# ESP32-C2 register map
Vendor: ESPRESSIF SYSTEMS (SHANGHAI) CO., LTD.; Series: ESP32-C2; File version: 4
CPU: RV32IMC r0p0, little endian, no MPU, no FPU, 4 interrupt priority bits
Address unit: 32 bits
Registers are 32-bit, read-write, reset 0x0 unless marked. A register's access mark holds for its fields unless they carry their own. Offsets are from the block's base; [hi:lo] are bit positions; {n}, {i} and the like mark numbered series.

## APB_CTRL — Advanced Peripheral Bus Controller
Base 0x60026000
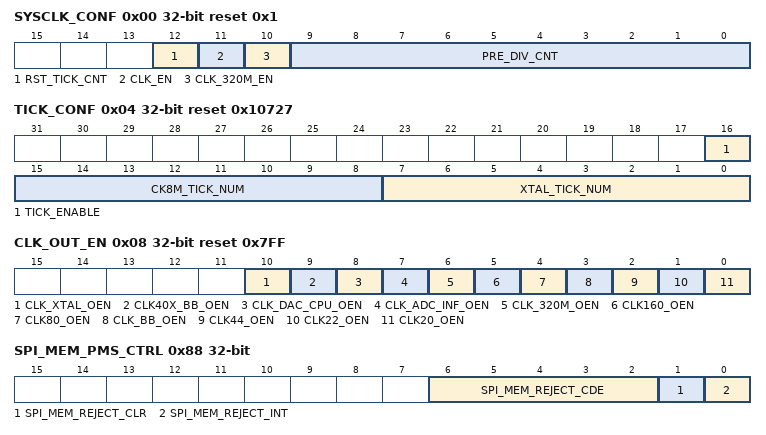
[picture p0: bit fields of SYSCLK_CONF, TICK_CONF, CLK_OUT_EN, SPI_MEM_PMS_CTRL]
0x00 SYSCLK_CONF reset 0x1 — APB_CTRL_SYSCLK_CONF_REG
  [12] RST_TICK_CNT — reg_rst_tick_cnt
  [11] CLK_EN — reg_clk_en
  [10] CLK_320M_EN — reg_clk_320m_en
  [9:0] PRE_DIV_CNT — reg_pre_div_cnt
0x04 TICK_CONF reset 0x10727 — APB_CTRL_TICK_CONF_REG
  [16] TICK_ENABLE — reg_tick_enable
  [15:8] CK8M_TICK_NUM — reg_ck8m_tick_num
  [7:0] XTAL_TICK_NUM — reg_xtal_tick_num
0x08 CLK_OUT_EN reset 0x7FF — APB_CTRL_CLK_OUT_EN_REG
  [10] CLK_XTAL_OEN — reg_clk_xtal_oen
  [9] CLK40X_BB_OEN — reg_clk40x_bb_oen
  [8] CLK_DAC_CPU_OEN — reg_clk_dac_cpu_oen
  [7] CLK_ADC_INF_OEN — reg_clk_adc_inf_oen
  [6] CLK_320M_OEN — reg_clk_320m_oen
  [5] CLK160_OEN — reg_clk160_oen
  [4] CLK80_OEN — reg_clk80_oen
  [3] CLK_BB_OEN — reg_clk_bb_oen
  [2] CLK44_OEN — reg_clk44_oen
  [1] CLK22_OEN — reg_clk22_oen
  [0] CLK20_OEN — reg_clk20_oen
0x0C WIFI_BB_CFG — APB_CTRL_WIFI_BB_CFG_REG
  [31:0] WIFI_BB_CFG — reg_wifi_bb_cfg
0x10 WIFI_BB_CFG_2 — APB_CTRL_WIFI_BB_CFG_2_REG
  [31:0] WIFI_BB_CFG_2 — reg_wifi_bb_cfg_2
0x14 WIFI_CLK_EN reset 0xFFFCE030 — APB_CTRL_WIFI_CLK_EN_REG
  [31:0] WIFI_CLK_EN — reg_wifi_clk_en
0x18 WIFI_RST_EN — APB_CTRL_WIFI_RST_EN_REG
  [31:0] WIFI_RST — reg_wifi_rst
0x1C HOST_INF_SEL — APB_CTRL_HOST_INF_SEL_REG
  [7:0] PERI_IO_SWAP — reg_peri_io_swap
0x20 EXT_MEM_PMS_LOCK — APB_CTRL_EXT_MEM_PMS_LOCK_REG
  [0] EXT_MEM_PMS_LOCK — reg_ext_mem_pms_lock
{0x28+4i} FLASH_ACE{i}_ATTR reset 0x3 (i=0..3) — APB_CTRL_FLASH_ACE{i}_ATTR_REG
  [1:0] FLASH_ACE{i}_ATTR — reg_flash_ace{i}_attr
0x38 FLASH_ACE0_ADDR — APB_CTRL_FLASH_ACE0_ADDR_REG
  [31:0] S — reg_flash_ace0_addr_s
0x3C FLASH_ACE1_ADDR reset 0x400000 — APB_CTRL_FLASH_ACE1_ADDR_REG
  [31:0] S — reg_flash_ace1_addr_s
0x40 FLASH_ACE2_ADDR reset 0x800000 — APB_CTRL_FLASH_ACE2_ADDR_REG
  [31:0] S — reg_flash_ace2_addr_s
0x44 FLASH_ACE3_ADDR reset 0xC00000 — APB_CTRL_FLASH_ACE3_ADDR_REG
  [31:0] S — reg_flash_ace3_addr_s
{0x48+4i} FLASH_ACE{i}_SIZE reset 0x400 (i=0..3) — APB_CTRL_FLASH_ACE{i}_SIZE_REG
  [12:0] FLASH_ACE{i}_SIZE — reg_flash_ace{i}_size
0x88 SPI_MEM_PMS_CTRL access per field — APB_CTRL_SPI_MEM_PMS_CTRL_REG
  [6:2] SPI_MEM_REJECT_CDE ro — reg_spi_mem_reject_cde
  [1] SPI_MEM_REJECT_CLR wo — reg_spi_mem_reject_clr
  [0] SPI_MEM_REJECT_INT ro — reg_spi_mem_reject_int
0x8C SPI_MEM_REJECT_ADDR ro — APB_CTRL_SPI_MEM_REJECT_ADDR_REG
  [31:0] SPI_MEM_REJECT_ADDR — reg_spi_mem_reject_addr
0x90 SDIO_CTRL — APB_CTRL_SDIO_CTRL_REG
  [0] SDIO_WIN_ACCESS_EN — reg_sdio_win_access_en
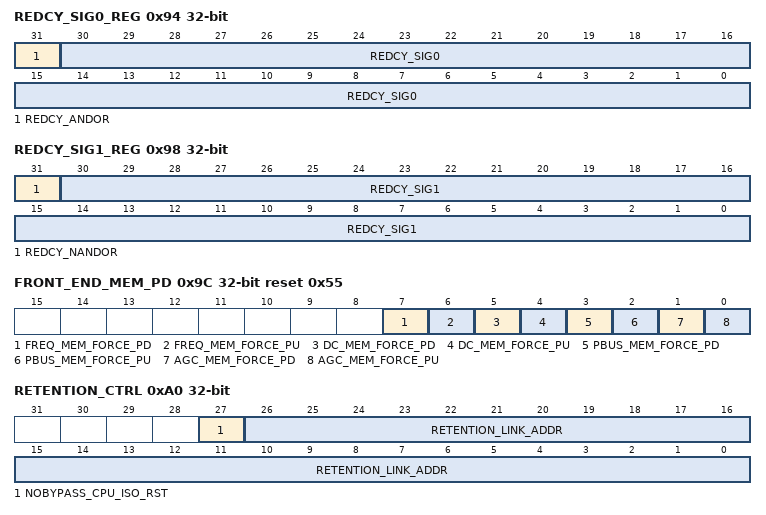
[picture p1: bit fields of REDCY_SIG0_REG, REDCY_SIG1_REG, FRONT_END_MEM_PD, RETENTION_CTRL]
0x94 REDCY_SIG0_REG access per field — APB_CTRL_REDCY_SIG0_REG_REG
  [31] REDCY_ANDOR ro — reg_redcy_andor
  [30:0] REDCY_SIG0 rw — reg_redcy_sig0
0x98 REDCY_SIG1_REG access per field — APB_CTRL_REDCY_SIG1_REG_REG
  [31] REDCY_NANDOR ro — reg_redcy_nandor
  [30:0] REDCY_SIG1 rw — reg_redcy_sig1
0x9C FRONT_END_MEM_PD reset 0x55 — APB_CTRL_FRONT_END_MEM_PD_REG
  [7] FREQ_MEM_FORCE_PD — reg_freq_mem_force_pd
  [6] FREQ_MEM_FORCE_PU — reg_freq_mem_force_pu
  [5] DC_MEM_FORCE_PD — reg_dc_mem_force_pd
  [4] DC_MEM_FORCE_PU — reg_dc_mem_force_pu
  [3] PBUS_MEM_FORCE_PD — reg_pbus_mem_force_pd
  [2] PBUS_MEM_FORCE_PU — reg_pbus_mem_force_pu
  [1] AGC_MEM_FORCE_PD — reg_agc_mem_force_pd
  [0] AGC_MEM_FORCE_PU — reg_agc_mem_force_pu
0xA0 RETENTION_CTRL — APB_CTRL_RETENTION_CTRL_REG
  [27] NOBYPASS_CPU_ISO_RST — reg_nobypass_cpu_iso_rst
  [26:0] RETENTION_LINK_ADDR — reg_retention_link_addr
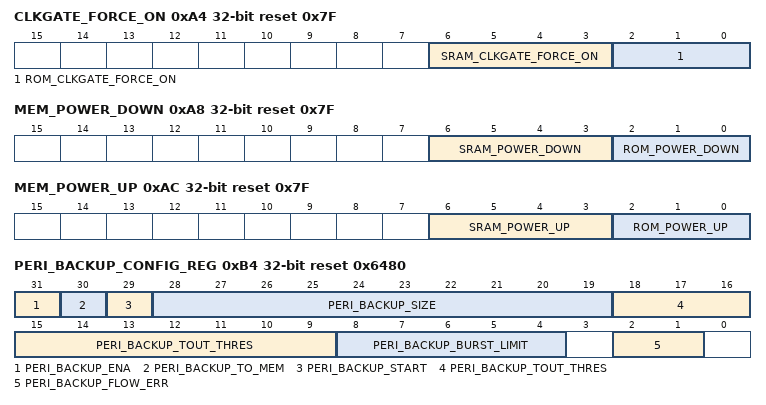
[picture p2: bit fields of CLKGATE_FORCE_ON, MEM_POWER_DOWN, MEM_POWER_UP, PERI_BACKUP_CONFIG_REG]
0xA4 CLKGATE_FORCE_ON reset 0x7F — Memory power configuration registers
  [6:3] SRAM_CLKGATE_FORCE_ON — Set the bit to 1 to force sram always have clock, for low power can clear to 0 then only when have access the sram have clock
  [2:0] ROM_CLKGATE_FORCE_ON — Set the bit to 1 to force rom always have clock, for low power can clear to 0 then only when have access the rom have clock
0xA8 MEM_POWER_DOWN reset 0x7F — Memory power configuration registers
  [6:3] SRAM_POWER_DOWN — Set 1 to let sram power down
  [2:0] ROM_POWER_DOWN — Set 1 to let rom power down
0xAC MEM_POWER_UP reset 0x7F — Memory power configuration registers
  [6:3] SRAM_POWER_UP — Set 1 to let sram power up
  [2:0] ROM_POWER_UP — Set 1 to let rom power up
0xB0 RND_DATA ro — APB_CTRL_RND_DATA_REG
  [31:0] RND_DATA — reg_rnd_data
0xB4 PERI_BACKUP_CONFIG_REG access per field reset 0x6480 — APB_CTRL_PERI_BACKUP_CONFIG_REG_REG
  [31] PERI_BACKUP_ENA rw — reg_peri_backup_ena
  [30] PERI_BACKUP_TO_MEM rw — reg_peri_backup_to_mem
  [29] PERI_BACKUP_START wo — reg_peri_backup_start
  [28:19] PERI_BACKUP_SIZE rw — reg_peri_backup_size
  [18:9] PERI_BACKUP_TOUT_THRES rw — reg_peri_backup_tout_thres
  [8:4] PERI_BACKUP_BURST_LIMIT rw — reg_peri_backup_burst_limit
  [2:1] PERI_BACKUP_FLOW_ERR ro — reg_peri_backup_flow_err
0xB8 PERI_BACKUP_APB_ADDR_REG — APB_CTRL_PERI_BACKUP_APB_ADDR_REG_REG
  [31:0] BACKUP_APB_START_ADDR — reg_backup_apb_start_addr
0xBC PERI_BACKUP_MEM_ADDR_REG — APB_CTRL_PERI_BACKUP_MEM_ADDR_REG_REG
  [31:0] BACKUP_MEM_START_ADDR — reg_backup_mem_start_addr
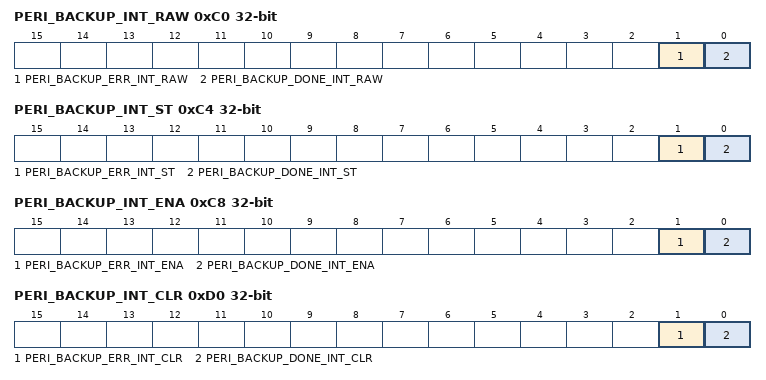
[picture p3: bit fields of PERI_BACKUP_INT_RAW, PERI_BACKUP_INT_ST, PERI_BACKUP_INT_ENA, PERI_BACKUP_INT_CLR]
0xC0 PERI_BACKUP_INT_RAW ro — APB_CTRL_PERI_BACKUP_INT_RAW_REG
  [1] PERI_BACKUP_ERR_INT_RAW — reg_peri_backup_err_int_raw
  [0] PERI_BACKUP_DONE_INT_RAW — reg_peri_backup_done_int_raw
0xC4 PERI_BACKUP_INT_ST ro — APB_CTRL_PERI_BACKUP_INT_ST_REG
  [1] PERI_BACKUP_ERR_INT_ST — reg_peri_backup_err_int_st
  [0] PERI_BACKUP_DONE_INT_ST — reg_peri_backup_done_int_st
0xC8 PERI_BACKUP_INT_ENA — APB_CTRL_PERI_BACKUP_INT_ENA_REG
  [1] PERI_BACKUP_ERR_INT_ENA — reg_peri_backup_err_int_ena
  [0] PERI_BACKUP_DONE_INT_ENA — reg_peri_backup_done_int_ena
0xD0 PERI_BACKUP_INT_CLR wo — APB_CTRL_PERI_BACKUP_INT_CLR_REG
  [1] PERI_BACKUP_ERR_INT_CLR — reg_peri_backup_err_int_clr
  [0] PERI_BACKUP_DONE_INT_CLR — reg_peri_backup_done_int_clr
0x3FC DATE reset 0x2106080 — APB_CTRL_DATE_REG
  [31:0] DATE — reg_dateVersion control

## Notices in the file
Copyright 2022 Espressif Systems (Shanghai) PTE LTD
Licensed under the Apache License, Version 2.0 (the "License");
you may not use this file except in compliance with the License.
You may obtain a copy of the License at
http://www.apache.org/licenses/LICENSE-2.0
Unless required by applicable law or agreed to in writing, software
distributed under the License is distributed on an "AS IS" BASIS,
WITHOUT WARRANTIES OR CONDITIONS OF ANY KIND, either express or implied.
See the License for the specific language governing permissions and
limitations under the License.
